# MSP430FR6972 register map
Registers are 16-bit, read-write, reset 0x0 unless marked. A register's access mark holds for its fields unless they carry their own. Offsets are from the block's base; lines under a group give offsets from that group; [hi:lo] are bit positions; {n}, {i} and the like mark numbered series; 'fields as' and 'values as' point back to an identical list; <NAME> marks a mode.

## Memory map
0x00000100 SFR — SFR Special Function Registers
0x00000120 PMM — PMM Power Management System
0x00000140 FRAM
0x00000150 CRC16
0x00000158 RC_FRAM — RC RAM Control Module (FRAM)
0x0000015C WATCHDOG_TIMER
0x00000160 CS — CS Clock System
0x00000180 SYS — SYS System Module
0x000001B0 SHARED_REFERENCE
0x00000200 PORT_1_2
0x00000220 PORT_3_4
0x00000240 PORT_5_6
0x00000260 PORT_7
0x00000280 PORT_9
0x00000320 PORT_J
0x00000340 TIMER_0_A3
0x00000380 TIMER_1_A3
0x000003C0 TIMER_0_B7
0x00000400 TIMER_2_A2
0x0000043E CAPACITIVE_TOUCH_IO_0
0x00000440 TIMER_3_A5
0x0000047E CAPACITIVE_TOUCH_IO_1
0x000004A0 RTC_C_REAL_TIME_CLOCK
0x000004C0 MPY_16 — MPY 16 Multiplier 16 Bit Mode
0x000004D0 MPY_32 — MPY 32 Multiplier 32 Bit Mode
0x00000500 DMA
0x000005A0 MPU
0x000005C0 USCI_A0_UART_MODE
0x000005C0 USCI_A0_SPI_MODE
0x000005E0 USCI_A1_UART_MODE
0x000005E0 USCI_A1_SPI_MODE
0x00000640 USCI_B0_I2C_MODE
0x00000640 USCI_B0_SPI_MODE
0x00000680 USCI_B1_I2C_MODE
0x00000680 USCI_B1_SPI_MODE
0x00000800 ADC12
0x000008C0 COMPARATOR_E
0x00000980 CRC32
0x000009C0 AES_ACCELERATOR
0x00000A00 LCD_C
0x0000FF80 _INTERRUPTS

## Interrupts
27 AES256 (_INTERRUPTS) — 0xFFC6 AES256
28 RTC (_INTERRUPTS) — 0xFFC8 RTC
29 LCD_C (_INTERRUPTS) — 0xFFCA LCD C
30 PORT4 (_INTERRUPTS) — 0xFFCC Port 4
31 PORT3 (_INTERRUPTS) — 0xFFCE Port 3
32 TIMER3_A1 (_INTERRUPTS) — 0xFFD0 Timer3_A2 CC1, TA
33 TIMER3_A0 (_INTERRUPTS) — 0xFFD2 Timer3_A2 CC0
34 PORT2 (_INTERRUPTS) — 0xFFD4 Port 2
35 TIMER2_A1 (_INTERRUPTS) — 0xFFD6 Timer2_A3 CC1, TA
36 TIMER2_A0 (_INTERRUPTS) — 0xFFD8 Timer2_A3 CC0
37 PORT1 (_INTERRUPTS) — 0xFFDA Port 1
38 TIMER1_A1 (_INTERRUPTS) — 0xFFDC Timer1_A3 CC1-2, TA1
39 TIMER1_A0 (_INTERRUPTS) — 0xFFDE Timer1_A3 CC0
40 DMA (_INTERRUPTS) — 0xFFE0 DMA
41 USCI_B1 (_INTERRUPTS) — 0xFFE2 USCI B1 Receive/Transmit
42 USCI_A1 (_INTERRUPTS) — 0xFFE4 USCI A1 Receive/Transmit
43 TIMER0_A1 (_INTERRUPTS) — 0xFFE6 Timer0_A5 CC1-4, TA
44 TIMER0_A0 (_INTERRUPTS) — 0xFFE8 Timer0_A5 CC0
45 ADC12 (_INTERRUPTS) — 0xFFEA ADC
46 USCI_B0 (_INTERRUPTS) — 0xFFEC USCI B0 Receive/Transmit
47 USCI_A0 (_INTERRUPTS) — 0xFFEE USCI A0 Receive/Transmit
49 WDT (_INTERRUPTS) — 0xFFF2 Watchdog Timer
50 TIMER0_B1 (_INTERRUPTS) — 0xFFF4 Timer0_B3 CC1-2, TB
51 TIMER0_B0 (_INTERRUPTS) — 0xFFF6 Timer0_B3 CC0
52 COMP_E (_INTERRUPTS) — 0xFFF8 Comparator E
53 UNMI (_INTERRUPTS) — 0xFFFA User Non-maskable
54 SYSNMI (_INTERRUPTS) — 0xFFFC System Non-maskable

## Further device data
msp430_svd: version=0.2.0 commit_hash=92826fe

## PORT_1_2
Base 0x00000200
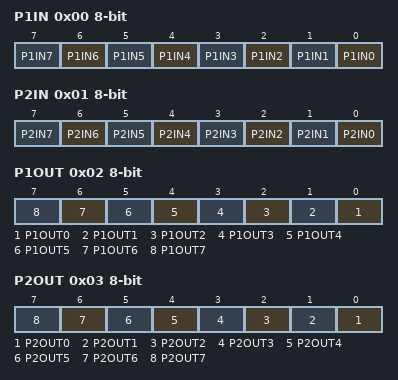
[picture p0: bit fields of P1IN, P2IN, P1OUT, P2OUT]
0x00 P1IN 8-bit — Port 1 Input
  [n] P1IN{n} (n=0..7)
0x01 P2IN 8-bit — Port 2 Input
  [n] P2IN{n} (n=0..7)
0x02 P1OUT 8-bit — Port 1 Output
  [n] P1OUT{n} (n=0..7)
0x03 P2OUT 8-bit — Port 2 Output
  [n] P2OUT{n} (n=0..7)
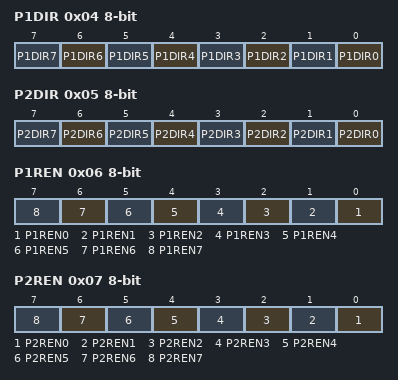
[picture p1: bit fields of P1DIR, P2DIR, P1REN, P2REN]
0x04 P1DIR 8-bit — Port 1 Direction
  [n] P1DIR{n} (n=0..7)
0x05 P2DIR 8-bit — Port 2 Direction
  [n] P2DIR{n} (n=0..7)
0x06 P1REN 8-bit — Port 1 Resistor Enable
  [n] P1REN{n} (n=0..7)
0x07 P2REN 8-bit — Port 2 Resistor Enable
  [n] P2REN{n} (n=0..7)
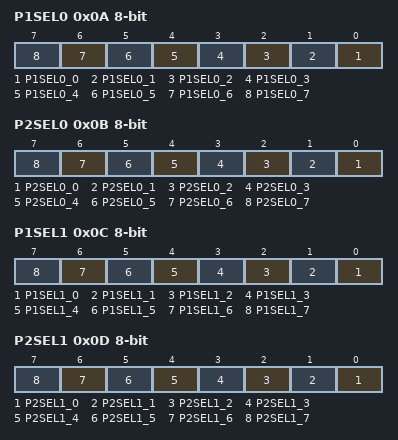
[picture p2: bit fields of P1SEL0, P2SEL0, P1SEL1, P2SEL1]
0x0A P1SEL0 8-bit — Port 1 Selection 0
  [n] P1SEL0_{n} (n=0..7)
0x0B P2SEL0 8-bit — Port 2 Selection 0
  [n] P2SEL0_{n} (n=0..7)
0x0C P1SEL1 8-bit — Port 1 Selection 1
  [n] P1SEL1_{n} (n=0..7)
0x0D P2SEL1 8-bit — Port 2 Selection 1
  [n] P2SEL1_{n} (n=0..7)
0x0E P1IV — Port 1 Interrupt Vector Word
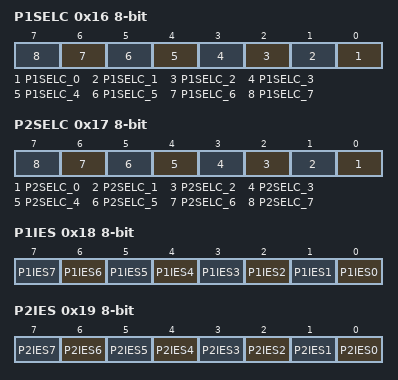
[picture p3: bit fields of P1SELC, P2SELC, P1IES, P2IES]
0x16 P1SELC 8-bit — Port 1 Complement Selection
  [n] P1SELC_{n} (n=0..7)
0x17 P2SELC 8-bit — Port 2 Complement Selection
  [n] P2SELC_{n} (n=0..7)
0x18 P1IES 8-bit — Port 1 Interrupt Edge Select
  [n] P1IES{n} (n=0..7)
0x19 P2IES 8-bit — Port 2 Interrupt Edge Select
  [n] P2IES{n} (n=0..7)
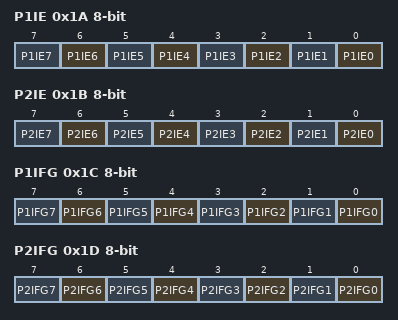
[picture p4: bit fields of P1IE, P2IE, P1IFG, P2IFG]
0x1A P1IE 8-bit — Port 1 Interrupt Enable
  [n] P1IE{n} (n=0..7)
0x1B P2IE 8-bit — Port 2 Interrupt Enable
  [n] P2IE{n} (n=0..7)
0x1C P1IFG 8-bit — Port 1 Interrupt Flag
  [n] P1IFG{n} (n=0..7)
0x1D P2IFG 8-bit — Port 2 Interrupt Flag
  [n] P2IFG{n} (n=0..7)
0x1E P2IV — Port 2 Interrupt Vector Word
